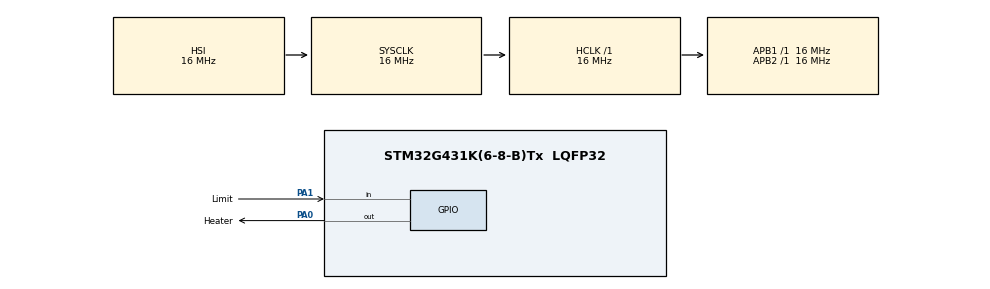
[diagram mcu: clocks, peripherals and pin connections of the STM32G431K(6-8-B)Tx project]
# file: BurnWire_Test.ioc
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Mcu.Family=STM32G4
Mcu.Name=STM32G431K(6-8-B)Tx
Mcu.Package=LQFP32
NVIC.PriorityGroup=NVIC_PRIORITYGROUP_4
PA0.GPIO_Label=Heater
PA0.Signal=GPIO_Output
PA1.GPIO_Label=Limit
PA1.GPIO_PuPd=GPIO_PULLUP
PA1.Signal=GPIO_Input
PA13.Mode=Serial_Wire
PA13.Signal=SYS_JTMS-SWDIO
PA14.Mode=Serial_Wire
PA14.Signal=SYS_JTCK-SWCLK
ProjectManager.HeapSize=0x200
ProjectManager.StackSize=0x400
ProjectManager.TargetToolchain=STM32CubeIDE
RCC.AHBFreq_Value=16000000
RCC.APB1Freq_Value=16000000
RCC.APB1TimFreq_Value=16000000
RCC.APB2Freq_Value=16000000
RCC.APB2TimFreq_Value=16000000
RCC.CortexFreq_Value=16000000
RCC.EXTERNAL_CLOCK_VALUE=12288000
RCC.HCLKFreq_Value=16000000
RCC.HSE_VALUE=8000000
RCC.HSI48_VALUE=48000000
RCC.HSI_VALUE=16000000
RCC.LSE_VALUE=32768
RCC.SYSCLKFreq_VALUE=16000000
RCC.USBFreq_Value=64000000
RCC.VCOOutputFreq_Value=128000000
VP_SYS_VS_DBSignals.Mode=DisableDeadBatterySignals
board=custom

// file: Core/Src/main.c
/*
 * Copyright (c) 2026 STMicroelectronics.
 * All rights reserved.
 *
 * This software is licensed under terms that can be found in the LICENSE file
 * in the root directory of this software component.
 * If no LICENSE file comes with this software, it is provided AS-IS.
 */

#include "main.h"

void SystemClock_Config(void);
static void MX_GPIO_Init(void);

/* USER CODE BEGIN 0 */
volatile GPIO_PinState limitState;
/* USER CODE END 0 */

int main(void)
{
    HAL_Init();
    SystemClock_Config();
    MX_GPIO_Init();

    /* USER CODE BEGIN 2 */
    HAL_GPIO_WritePin(GPIOA, GPIO_PIN_0, GPIO_PIN_RESET);
    int deployCommand = 0;
    uint32_t startTime = 0;
    int heaterStarted = 0;
    uint32_t timeoutMs = 10000;
    /* USER CODE END 2 */

    while (1)
    {
    	  /* USER CODE BEGIN 3 */
    	if (heaterStarted == 0 && deployCommand == 1 && HAL_GPIO_ReadPin(GPIOA, GPIO_PIN_1) == 0){
    		startTime =  HAL_GetTick();
    		HAL_GPIO_WritePin(GPIOA,GPIO_PIN_0,GPIO_PIN_SET);
    		heaterStarted = 1;
    		}
    	if (HAL_GPIO_ReadPin(GPIOA,GPIO_PIN_1) == 1){
    	    		HAL_GPIO_WritePin(GPIOA, GPIO_PIN_0, GPIO_PIN_RESET);
    	    	}
    	if (heaterStarted == 1 && (HAL_GetTick()-startTime) >= timeoutMs   ){
    		HAL_GPIO_WritePin(GPIOA, GPIO_PIN_0, GPIO_PIN_RESET);
    	}

    }
    /* USER CODE END 3 */
   }

void SystemClock_Config(void)
{
    RCC_OscInitTypeDef oscillator = {0};
    RCC_ClkInitTypeDef clock = {0};

    HAL_PWREx_ControlVoltageScaling(PWR_REGULATOR_VOLTAGE_SCALE1);

    oscillator.OscillatorType = RCC_OSCILLATORTYPE_HSI;
    oscillator.HSIState = RCC_HSI_ON;
    oscillator.HSICalibrationValue = RCC_HSICALIBRATION_DEFAULT;
    oscillator.PLL.PLLState = RCC_PLL_NONE;

    if (HAL_RCC_OscConfig(&oscillator) != HAL_OK)
    {
        Error_Handler();
    }

    clock.ClockType = RCC_CLOCKTYPE_HCLK
                    | RCC_CLOCKTYPE_SYSCLK
                    | RCC_CLOCKTYPE_PCLK1
                    | RCC_CLOCKTYPE_PCLK2;

    clock.SYSCLKSource = RCC_SYSCLKSOURCE_HSI;
    clock.AHBCLKDivider = RCC_SYSCLK_DIV1;
    clock.APB1CLKDivider = RCC_HCLK_DIV1;
    clock.APB2CLKDivider = RCC_HCLK_DIV1;

    if (HAL_RCC_ClockConfig(&clock, FLASH_LATENCY_0) != HAL_OK)
    {
        Error_Handler();
    }
}

static void MX_GPIO_Init(void)
{
    GPIO_InitTypeDef gpio = {0};

    __HAL_RCC_GPIOA_CLK_ENABLE();

    HAL_GPIO_WritePin(Heater_GPIO_Port, Heater_Pin, GPIO_PIN_RESET);

    gpio.Pin = Heater_Pin;
    gpio.Mode = GPIO_MODE_OUTPUT_PP;
    gpio.Pull = GPIO_NOPULL;
    gpio.Speed = GPIO_SPEED_FREQ_LOW;
    HAL_GPIO_Init(Heater_GPIO_Port, &gpio);

    gpio.Pin = Limit_Pin;
    gpio.Mode = GPIO_MODE_INPUT;
    gpio.Pull = GPIO_PULLUP;
    HAL_GPIO_Init(Limit_GPIO_Port, &gpio);
}

void Error_Handler(void)
{
    __disable_irq();
    while (1)
    {
    }
}
